# SAM9X75D2G device description
Architecture: ARM926EJ-S; Family: SAM9; Series: SAM9X7
Registers are 32-bit, read-write, reset 0x0 unless marked. A register's access mark holds for its fields unless they carry their own. Offsets are from the block's base; [hi:lo] are bit positions; {n}, {i} and the like mark numbered series; <NAME> marks a mode.

## PIO — Parallel Input/Output Controller
Instances: PIOA 0xFFFFF400, PIOB 0xFFFFF600, PIOC 0xFFFFF800, PIOD 0xFFFFFA00
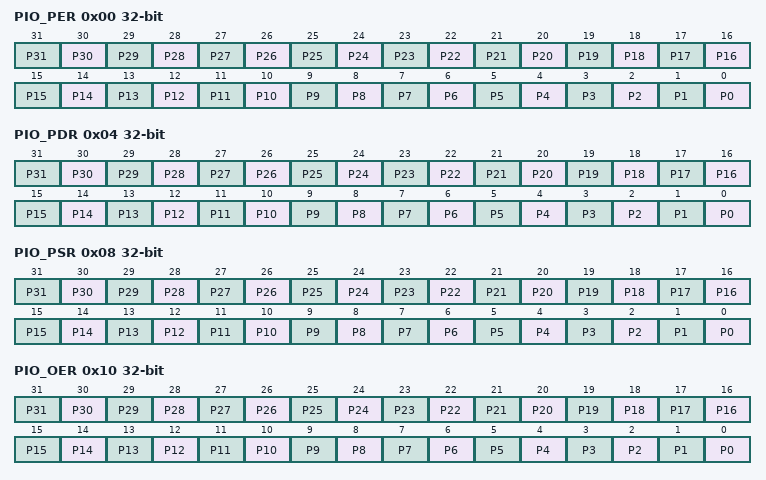
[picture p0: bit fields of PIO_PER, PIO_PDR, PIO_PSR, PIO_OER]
0x00 PIO_PER wo reset not defined — PIO Enable Register
  [all] fields
    0=No effect; 1=Enables the PIO to control the corresponding pin (disables peripheral control of the pin)
  [n] P{n} (n=0..31) — PIO Enable
0x04 PIO_PDR wo reset not defined (atomic clear of PIO_PSR) — PIO Disable Register
  [all] fields
    0=No effect; 1=Disables the PIO from controlling the corresponding pin (enables peripheral control of the pin)
  [n] P{n} (n=0..31) — PIO Disable
0x08 PIO_PSR ro reset not defined — PIO Status Register
  [all] fields
    0=PIO is inactive on the corresponding I/O line (peripheral is active); 1=PIO is active on the corresponding I/O line (peripheral is inactive)
  [n] P{n} (n=0..31) — PIO Status
0x10 PIO_OER wo reset not defined — Output Enable Register
  [all] fields
    0=No effect; 1=Enables the output on the I/O line
  [n] P{n} (n=0..31) — Output Enable
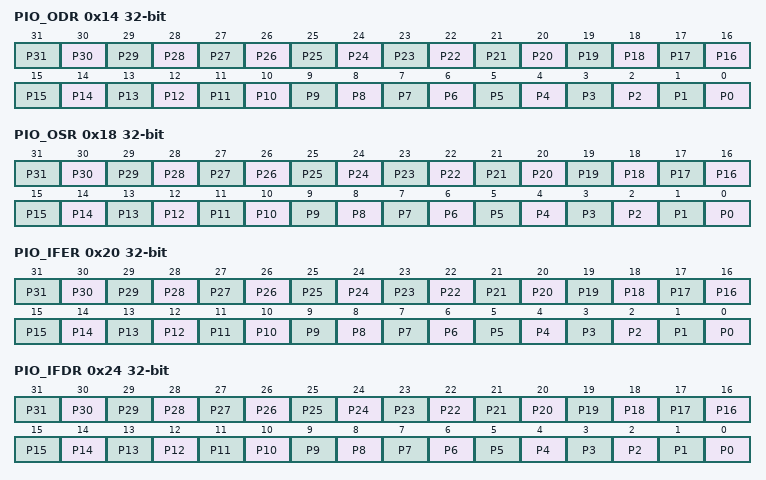
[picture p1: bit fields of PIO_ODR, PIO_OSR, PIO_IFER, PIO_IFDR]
0x14 PIO_ODR wo reset not defined (atomic clear of PIO_OSR) — Output Disable Register
  [all] fields
    0=No effect; 1=Disables the output on the I/O line
  [n] P{n} (n=0..31) — Output Disable
0x18 PIO_OSR ro — Output Status Register
  [all] fields
    0=The I/O line is a pure input; 1=The I/O line is enabled in output
  [n] P{n} (n=0..31) — Output Status
0x20 PIO_IFER wo reset not defined — Glitch Input Filter Enable Register
  [all] fields
    0=No effect; 1=Enables the input glitch filter on the I/O line
  [n] P{n} (n=0..31) — Input Filter Enable
0x24 PIO_IFDR wo reset not defined (atomic clear of PIO_IFSR) — Glitch Input Filter Disable Register
  [all] fields
    0=No effect; 1=Disables the input glitch filter on the I/O line
  [n] P{n} (n=0..31) — Input Filter Disable
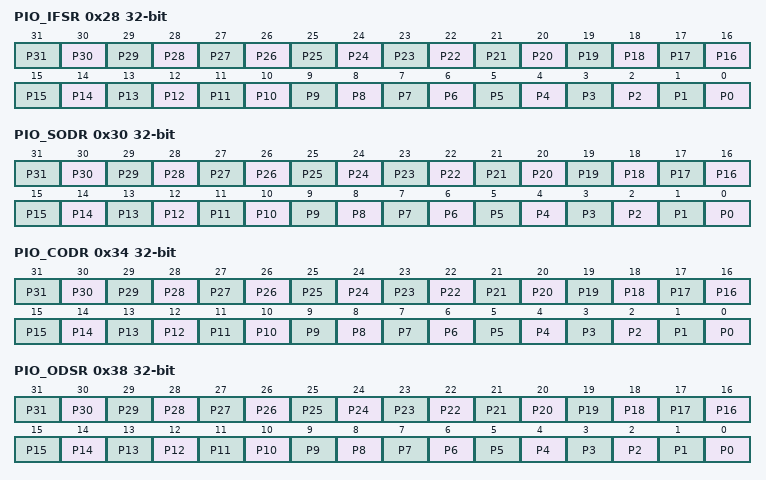
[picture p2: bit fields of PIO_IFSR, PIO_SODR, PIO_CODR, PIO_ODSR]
0x28 PIO_IFSR ro — Glitch Input Filter Status Register
  [all] fields
    0=The input glitch filter is disabled on the I/O line; 1=The input glitch filter is enabled on the I/O line
  [n] P{n} (n=0..31) — Input Filter Status
0x30 PIO_SODR wo reset not defined — Set Output Data Register
  [all] fields
    0=No effect; 1=Sets the data to be driven on the I/O line
  [n] P{n} (n=0..31) — Set Output Data
0x34 PIO_CODR wo reset not defined — Clear Output Data Register
  [all] fields
    0=No effect; 1=Clears the data to be driven on the I/O line
  [n] P{n} (n=0..31) — Clear Output Data
0x38 PIO_ODSR reset not defined — Output Data Status Register
  [all] fields
    0=The data to be driven on the I/O line is 0; 1=The data to be driven on the I/O line is 1
  [n] P{n} (n=0..31) — Output Data Status
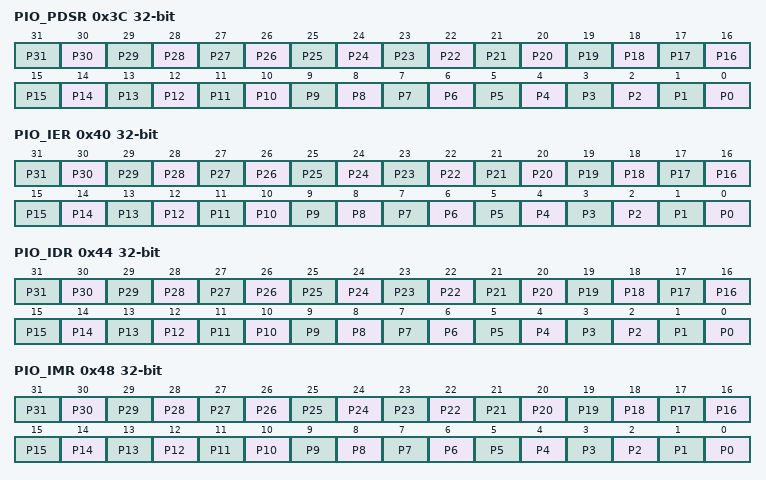
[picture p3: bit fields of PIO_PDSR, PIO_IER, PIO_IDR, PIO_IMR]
0x3C PIO_PDSR ro reset not defined — Pin Data Status Register
  [all] fields
    0=The I/O line is at level 0; 1=The I/O line is at level 1
  [n] P{n} (n=0..31) — Output Data Status
0x40 PIO_IER wo reset not defined (atomic set of PIO_IMR) — Interrupt Enable Register
  [all] fields
    0=No effect; 1=Enables the input change interrupt on the I/O line
  [n] P{n} (n=0..31) — Input Change Interrupt Enable
0x44 PIO_IDR wo reset not defined (atomic clear of PIO_IMR) — Interrupt Disable Register
  [all] fields
    0=No effect; 1=Disables the input change interrupt on the I/O line
  [n] P{n} (n=0..31) — Input Change Interrupt Disable
0x48 PIO_IMR ro — Interrupt Mask Register
  [all] fields
    0=Input change interrupt is disabled on the I/O line; 1=Input change interrupt is enabled on the I/O line
  [n] P{n} (n=0..31) — Input Change Interrupt Mask
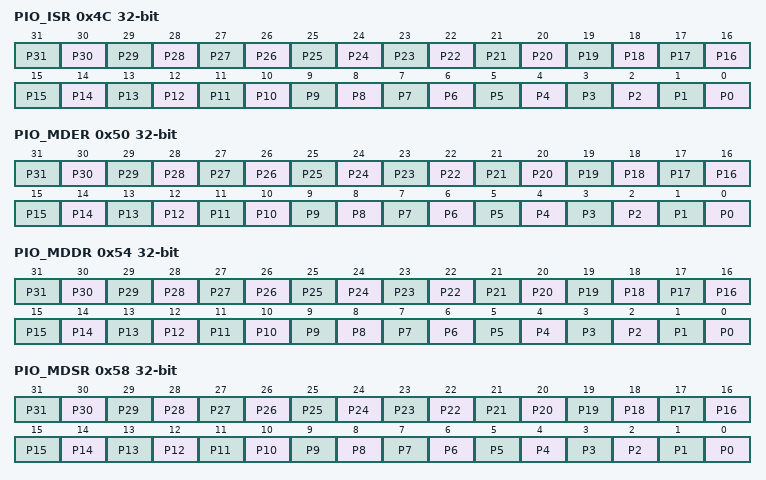
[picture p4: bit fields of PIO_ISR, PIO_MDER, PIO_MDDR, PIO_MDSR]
0x4C PIO_ISR ro — Interrupt Status Register
  [all] fields
    0=No input change has been detected on the I/O line since PIO_ISR was last read or since reset; 1=At least one input change has been detected on the I/O line since PIO_ISR was last read or since reset
  [n] P{n} (n=0..31) — Input Change Interrupt Status
0x50 PIO_MDER wo reset not defined — Multi-driver Enable Register
  [all] fields
    0=No effect; 1=Enables multi-drive on the I/O line
  [n] P{n} (n=0..31) — Multi-drive Enable
0x54 PIO_MDDR wo reset not defined (atomic clear of PIO_MDSR) — Multi-driver Disable Register
  [all] fields
    0=No effect; 1=Disables multi-drive on the I/O line
  [n] P{n} (n=0..31) — Multi-drive Disable
0x58 PIO_MDSR ro — Multi-driver Status Register
  [all] fields
    0=The multi-drive is disabled on the I/O line. The pin is driven at high- and low-level.; 1=The multi-drive is enabled on the I/O line. The pin is driven at low-level only.
  [n] P{n} (n=0..31) — Multi-drive Status
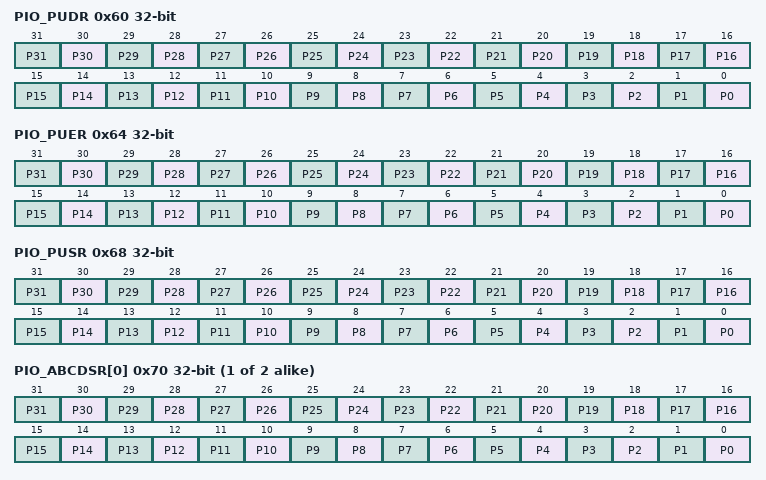
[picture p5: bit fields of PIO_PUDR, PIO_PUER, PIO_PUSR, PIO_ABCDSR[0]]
0x60 PIO_PUDR wo reset not defined (atomic clear of PIO_PUSR) — Pull-Up Disable Register
  [all] fields
    0=No effect; 1=Disables the pullup resistor on the I/O line
  [n] P{n} (n=0..31) — Pull-Up Disable
0x64 PIO_PUER wo reset not defined — Pull-Up Enable Register
  [all] fields
    0=No effect; 1=Enables the pullup resistor on the I/O line
  [n] P{n} (n=0..31) — Pull-Up Enable
0x68 PIO_PUSR ro reset not defined — Pad Pull-Up Status Register
  [all] fields
    0=Pullup resistor is enabled on the I/O line; 1=Pullup resistor is disabled on the I/O line
  [n] P{n} (n=0..31) — Pull-Up Status
{0x70+4i} PIO_ABCDSR[{i}] (i=0..1) — Peripheral ABCD Select Register 1
  [all] fields
    0=Assigns the I/O line to the Peripheral A function; 0=Assigns the I/O line to the Peripheral C function; 1=Assigns the I/O line to the Peripheral B function; 1=Assigns the I/O line to the Peripheral D function
  [n] P{n} (n=0..31) — Peripheral Select
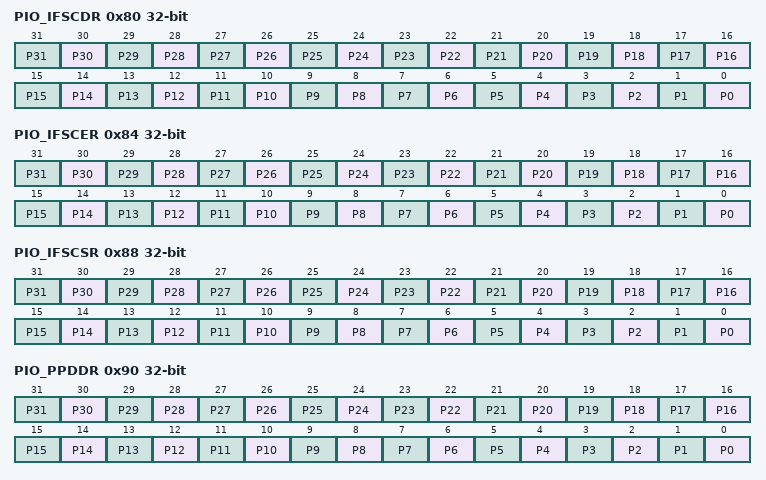
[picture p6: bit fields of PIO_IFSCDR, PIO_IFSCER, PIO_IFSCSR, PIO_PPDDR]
0x80 PIO_IFSCDR wo reset not defined (atomic clear of PIO_IFSCSR) — Input Filter Slow Clock Disable Register
  [all] fields
    0=No effect; 1=The glitch filter is able to filter glitches with a duration < tperipheral clock/2
  [n] P{n} (n=0..31) — Peripheral Clock Glitch Filtering Select
0x84 PIO_IFSCER wo reset not defined — Input Filter Slow Clock Enable Register
  [all] fields
    0=No effect; 1=The debouncing filter is able to filter pulses with a duration < tdiv_slck/2
  [n] P{n} (n=0..31) — Slow Clock Debouncing Filtering Select
0x88 PIO_IFSCSR ro — Input Filter Slow Clock Status Register
  [all] fields
    0=The glitch filter is able to filter glitches with a duration < tperipheral clock/2; 1=The debouncing filter is able to filter pulses with a duration < tdiv_slck/2
  [n] P{n} (n=0..31) — Glitch or Debouncing Filter Selection Status
0x8C PIO_SCDR — Slow Clock Divider Debouncing Register
  [13:0] DIV — Slow Clock Divider Selection for Debouncing
0x90 PIO_PPDDR wo reset not defined (atomic clear of PIO_PPDSR) — Pad Pull-Down Disable Register
  [all] fields
    0=No effect; 1=Disables the pulldown resistor on the I/O line
  [n] P{n} (n=0..31) — Pull-Down Disable
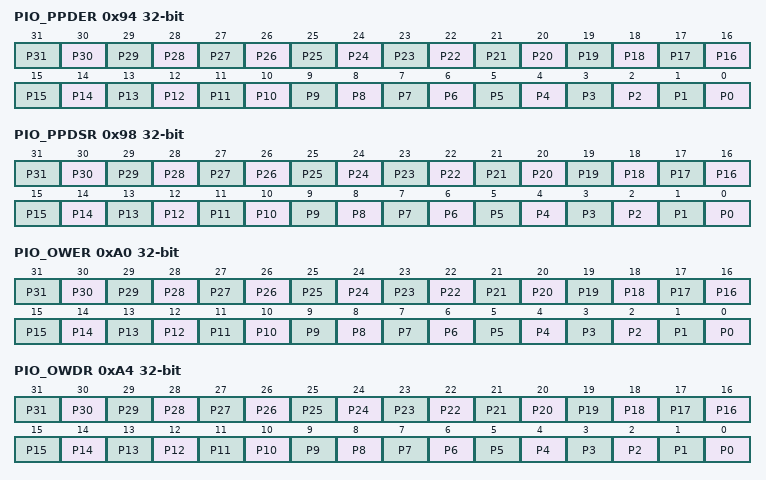
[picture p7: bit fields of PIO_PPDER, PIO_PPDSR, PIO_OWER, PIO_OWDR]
0x94 PIO_PPDER wo reset not defined — Pad Pull-Down Enable Register
  [all] fields
    0=No effect; 1=Enables the pulldown resistor on the I/O line
  [n] P{n} (n=0..31) — Pull-Down Enable
0x98 PIO_PPDSR ro reset not defined — Pad Pull-Down Status Register
  [all] fields
    0=Pulldown resistor is enabled on the I/O line; 1=Pulldown resistor is disabled on the I/O line
  [n] P{n} (n=0..31) — Pull-Down Status
0xA0 PIO_OWER wo reset not defined — Output Write Enable
  [all] fields
    0=No effect; 1=Enables writing PIO_ODSR for the I/O line
  [n] P{n} (n=0..31) — Output Write Enable
0xA4 PIO_OWDR wo reset not defined (atomic clear of PIO_OWSR) — Output Write Disable
  [all] fields
    0=No effect; 1=Disables writing PIO_ODSR for the I/O line
  [n] P{n} (n=0..31) — Output Write Disable
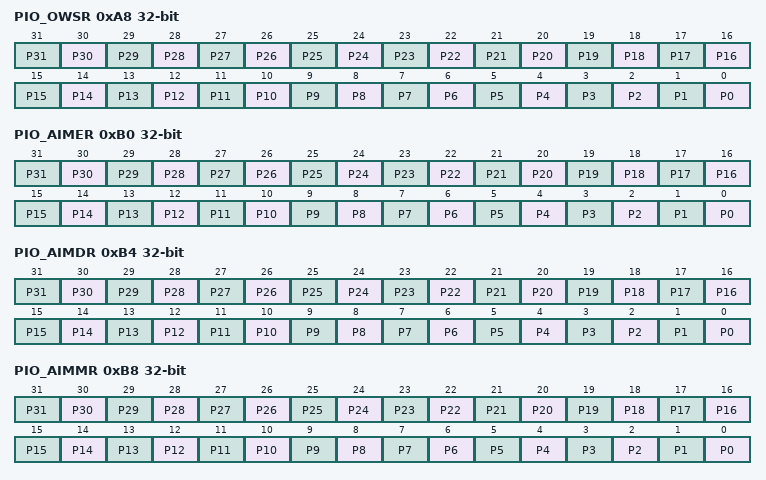
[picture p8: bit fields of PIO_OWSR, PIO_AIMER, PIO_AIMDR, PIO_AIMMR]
0xA8 PIO_OWSR ro — Output Write Status Register
  [all] fields
    0=Writing PIO_ODSR does not affect the I/O line; 1=Writing PIO_ODSR affects the I/O line
  [n] P{n} (n=0..31) — Output Write Status
0xB0 PIO_AIMER wo reset not defined — Additional Interrupt Modes Enable Register
  [all] fields
    0=No effect; 1=The interrupt source is the event described in PIO_ELSR and PIO_FRLHSR
  [n] P{n} (n=0..31) — Additional Interrupt Modes Enable
0xB4 PIO_AIMDR wo reset not defined — Additional Interrupt Modes Disable Register
  [all] fields
    0=No effect; 1=The Interrupt mode is set to the default Interrupt mode (Both-edge Detection)
  [n] P{n} (n=0..31) — Additional Interrupt Modes Disable
0xB8 PIO_AIMMR ro — Additional Interrupt Modes Mask Register
  [all] fields
    0=The interrupt source is a both-edge detection event; 1=The interrupt source is described by the registers PIO_ELSR and PIO_FRLHSR
  [n] P{n} (n=0..31) — IO Line Index
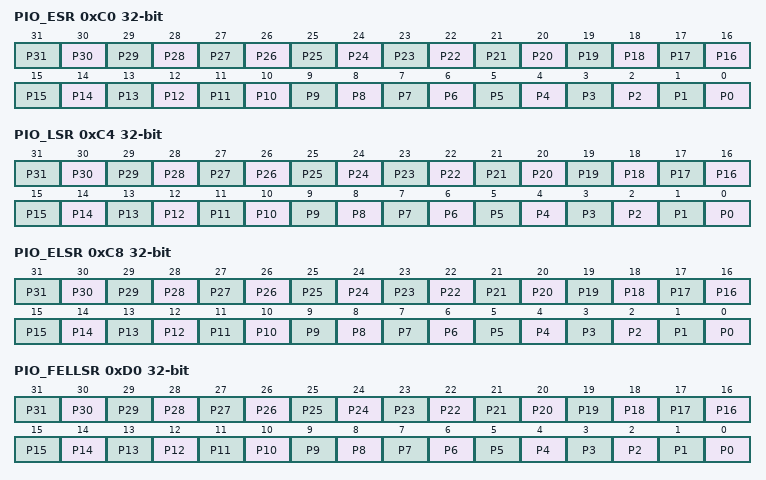
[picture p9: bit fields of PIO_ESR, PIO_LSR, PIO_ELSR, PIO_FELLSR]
0xC0 PIO_ESR wo reset not defined — Edge Select Register
  [all] fields
    0=No effect; 1=The interrupt source is an edge-detection event
  [n] P{n} (n=0..31) — Edge Interrupt Selection
0xC4 PIO_LSR wo reset not defined — Level Select Register
  [all] fields
    0=No effect; 1=The interrupt source is a level-detection event
  [n] P{n} (n=0..31) — Level Interrupt Selection
0xC8 PIO_ELSR ro — Edge/Level Status Register
  [all] fields
    0=The interrupt source is an edge-detection event; 1=The interrupt source is a level-detection event
  [n] P{n} (n=0..31) — Edge/Level Interrupt Source Selection
0xD0 PIO_FELLSR wo reset not defined — Falling Edge/Low-Level Select Register
  [all] fields
    0=No effect; 1=The interrupt source is set to a falling edge detection or low-level detection event, depending on PIO_ELSR
  [n] P{n} (n=0..31) — Falling Edge/Low-Level Interrupt Selection
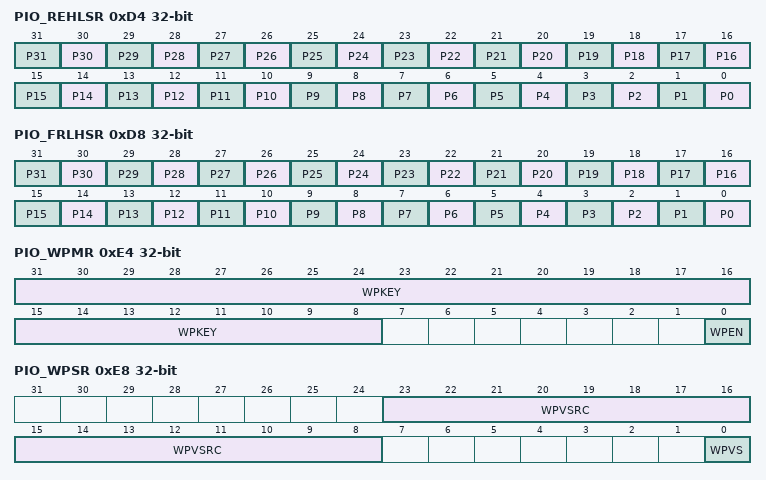
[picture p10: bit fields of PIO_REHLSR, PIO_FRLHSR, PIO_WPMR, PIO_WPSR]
0xD4 PIO_REHLSR wo reset not defined — Rising Edge/High-Level Select Register
  [all] fields
    0=No effect; 1=The interrupt source is set to a rising edge detection or high-level detection event, depending on PIO_ELSR
  [n] P{n} (n=0..31) — Rising Edge/High-Level Interrupt Selection
0xD8 PIO_FRLHSR ro — Fall/Rise - Low/High Status Register
  [all] fields
    0=The interrupt source is a falling edge detection (if PIO_ELSR = 0) or low-level detection event (if PIO_ELSR = 1); 1=The interrupt source is a rising edge detection (if PIO_ELSR = 0) or high-level detection event (if PIO_ELSR = 1)
  [n] P{n} (n=0..31) — Edge/Level Interrupt Source Selection
0xE4 PIO_WPMR — Write Protection Mode Register
  [31:8] WPKEY — Write Protection Key
    0x50494F=PASSWD (Writing any other value in this field aborts the write operation of the WPEN bit. Always reads as 0.)
  [0] WPEN — Write Protection Enable
    0=Disables the write protection if WPKEY corresponds to 0x50494F ("PIO" in ASCII); 1=Enables the write protection if WPKEY corresponds to 0x50494F ("PIO" in ASCII)
0xE8 PIO_WPSR ro — Write Protection Status Register
  [23:8] WPVSRC — Write Protection Violation Source
  [0] WPVS — Write Protection Violation Status
    0=No write protection violation has occurred since the last read of the PIO_WPSR; 1=A write protection violation has occurred since the last read of the PIO_WPSR. If this violation is an unauthorized attempt to write a protected register, the associated violation is reported into field WPVSRC.
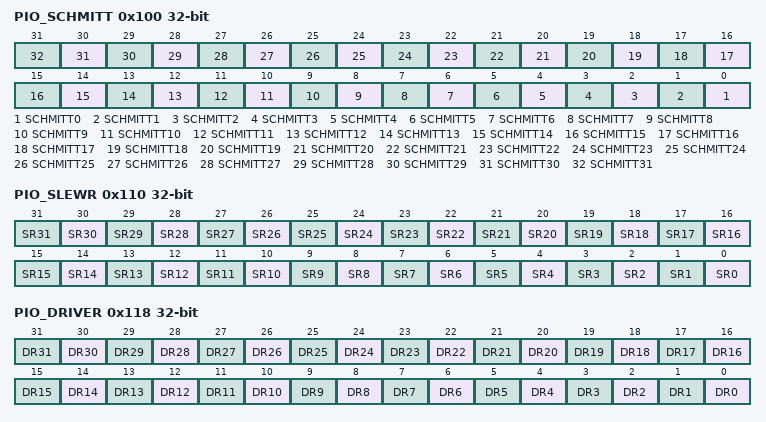
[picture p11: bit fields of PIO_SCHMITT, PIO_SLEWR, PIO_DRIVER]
0x100 PIO_SCHMITT — Schmitt Trigger Register
  [all] fields
    0=Schmitt trigger is enabled; 1=Schmitt trigger is disabled
  [n] SCHMITT{n} (n=0..31) — Schmitt Trigger Control
0x110 PIO_SLEWR — I/O Slewrate Control Register
  [all] fields
    0=DISABLED (No slewrate control.); 1=ENABLED (Slewrate controlled.)
  [n] SR{n} (n=0..31) — Slewrate Control for IO line {n}
0x118 PIO_DRIVER — I/O Drive Register
  [all] fields
    0=LOW (Lowest drive); 1=HIGH (Highest drive)
  [n] DR{n} (n=0..31) — Drive of I/O Line {n}
